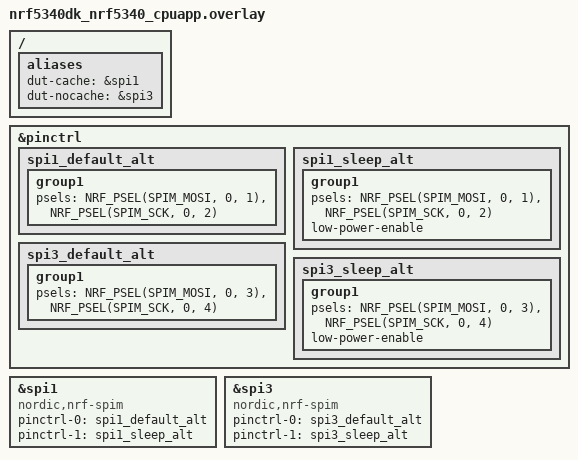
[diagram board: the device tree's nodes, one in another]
/ {
	aliases {
		dut-cache = &spi1;
		dut-nocache = &spi3;
	};
};

&pinctrl {
	spi1_default_alt: spi1_default_alt {
		group1 {
			psels = <NRF_PSEL(SPIM_MOSI, 0, 1)>,
				<NRF_PSEL(SPIM_SCK, 0, 2)>;
		};
	};

	spi1_sleep_alt: spi1_sleep_alt {
		group1 {
			psels = <NRF_PSEL(SPIM_MOSI, 0, 1)>,
				<NRF_PSEL(SPIM_SCK, 0, 2)>;
			low-power-enable;
		};
	};

	spi3_default_alt: spi3_default_alt {
		group1 {
			psels = <NRF_PSEL(SPIM_MOSI, 0, 3)>,
				<NRF_PSEL(SPIM_SCK, 0, 4)>;
		};
	};

	spi3_sleep_alt: spi3_sleep_alt {
		group1 {
			psels = <NRF_PSEL(SPIM_MOSI, 0, 3)>,
				<NRF_PSEL(SPIM_SCK, 0, 4)>;
			low-power-enable;
		};
	};
};

&spi1 {
	compatible = "nordic,nrf-spim";
	status = "okay";
	pinctrl-0 = <&spi1_default_alt>;
	pinctrl-1 = <&spi1_sleep_alt>;
	pinctrl-names = "default", "sleep";
};

&spi3 {
	compatible = "nordic,nrf-spim";
	status = "okay";
	pinctrl-0 = <&spi3_default_alt>;
	pinctrl-1 = <&spi3_sleep_alt>;
	pinctrl-names = "default", "sleep";
};
